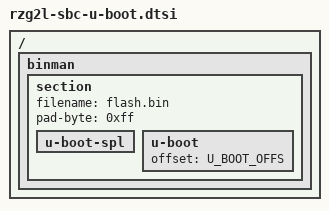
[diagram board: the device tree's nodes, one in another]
// SPDX-License-Identifier: GPL-2.0+
/*
 * Device Tree Source extras for U-Boot on RZ-CMN (RZ/G2L-SBC) board
 *
 * Contains BINMAN description for flash.bin
 */

#include <config.h>

#ifndef U_BOOT_OFFS
#define U_BOOT_OFFS 0x80000
#endif

/ {
	binman: binman {
		section {
			filename = "flash.bin";
			pad-byte = <0xff>;

			u-boot-spl {
			};

			u-boot {
				offset = <U_BOOT_OFFS>;
			};
		};
	};
};
